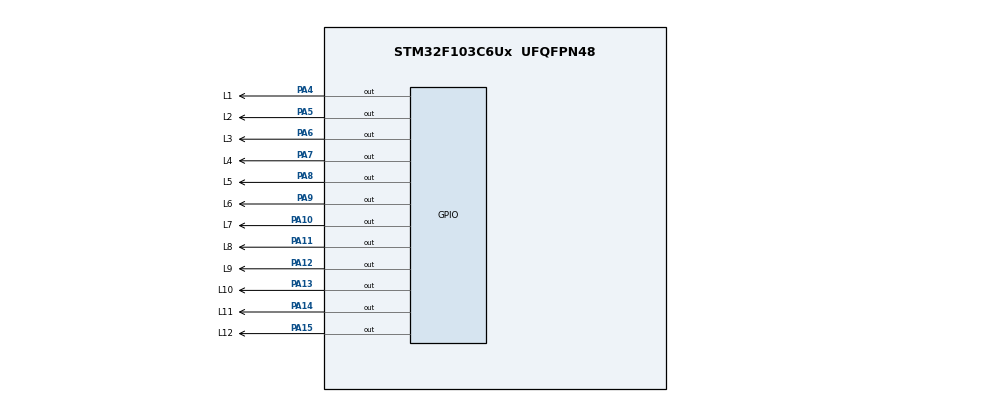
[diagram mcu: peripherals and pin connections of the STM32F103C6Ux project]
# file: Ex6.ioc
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Mcu.Family=STM32F1
Mcu.Name=STM32F103C6Ux
Mcu.Package=UFQFPN48
NVIC.PriorityGroup=NVIC_PRIORITYGROUP_4
PA10.GPIO_Label=L7
PA10.Signal=GPIO_Output
PA11.GPIO_Label=L8
PA11.Signal=GPIO_Output
PA12.GPIO_Label=L9
PA12.Signal=GPIO_Output
PA13.GPIO_Label=L10
PA13.Signal=GPIO_Output
PA14.GPIO_Label=L11
PA14.Signal=GPIO_Output
PA15.GPIO_Label=L12
PA15.Signal=GPIO_Output
PA4.GPIO_Label=L1
PA4.Signal=GPIO_Output
PA5.GPIO_Label=L2
PA5.Signal=GPIO_Output
PA6.GPIO_Label=L3
PA6.Signal=GPIO_Output
PA7.GPIO_Label=L4
PA7.Signal=GPIO_Output
PA8.GPIO_Label=L5
PA8.Signal=GPIO_Output
PA9.GPIO_Label=L6
PA9.Signal=GPIO_Output
ProjectManager.HeapSize=0x200
ProjectManager.StackSize=0x400
ProjectManager.TargetToolchain=STM32CubeIDE
RCC.APB1Freq_Value=8000000
RCC.APB2Freq_Value=8000000
board=custom

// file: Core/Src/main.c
/* USER CODE BEGIN Header */
/**
  ******************************************************************************
  * @file           : main.c
  * @brief          : Main program body
  ******************************************************************************
  * @attention
  *
  * Copyright (c) 2024 STMicroelectronics.
  * All rights reserved.
  *
  * This software is licensed under terms that can be found in the LICENSE file
  * in the root directory of this software component.
  * If no LICENSE file comes with this software, it is provided AS-IS.
  *
  ******************************************************************************
  */
/* USER CODE END Header */
#include "main.h"

void SystemClock_Config(void);
static void MX_GPIO_Init(void);

int main(void)
{

  /* MCU Configuration--------------------------------------------------------*/

  /* Reset of all peripherals, Initializes the Flash interface and the Systick. */
  HAL_Init();

  /* Configure the system clock */
  SystemClock_Config();

  /* Initialize all configured peripherals */
  MX_GPIO_Init();

  /* Infinite loop */
  /* USER CODE BEGIN WHILE */
  HAL_GPIO_WritePin(L1_GPIO_Port, L1_Pin, GPIO_PIN_SET);
  HAL_GPIO_WritePin(L2_GPIO_Port, L2_Pin, GPIO_PIN_SET);
  HAL_GPIO_WritePin(L3_GPIO_Port, L3_Pin, GPIO_PIN_SET);
  HAL_GPIO_WritePin(L4_GPIO_Port, L4_Pin, GPIO_PIN_SET);
  HAL_GPIO_WritePin(L5_GPIO_Port, L5_Pin, GPIO_PIN_SET);
  HAL_GPIO_WritePin(L6_GPIO_Port, L6_Pin, GPIO_PIN_SET);
  HAL_GPIO_WritePin(L7_GPIO_Port, L7_Pin, GPIO_PIN_SET);
  HAL_GPIO_WritePin(L8_GPIO_Port, L8_Pin, GPIO_PIN_SET);
  HAL_GPIO_WritePin(L9_GPIO_Port, L9_Pin, GPIO_PIN_SET);
  HAL_GPIO_WritePin(L10_GPIO_Port, L10_Pin, GPIO_PIN_SET);
  HAL_GPIO_WritePin(L11_GPIO_Port, L11_Pin, GPIO_PIN_SET);
  HAL_GPIO_WritePin(L12_GPIO_Port, L12_Pin, GPIO_PIN_SET);
  while (1)
  {
    /* USER CODE END WHILE */
	  HAL_GPIO_TogglePin(L1_GPIO_Port, L1_Pin);
	  HAL_Delay(1000);
	  HAL_GPIO_TogglePin(L2_GPIO_Port, L2_Pin);
	  HAL_Delay(1000);
	  HAL_GPIO_TogglePin(L3_GPIO_Port, L3_Pin);
	  HAL_Delay(1000);
	  HAL_GPIO_TogglePin(L4_GPIO_Port, L4_Pin);
	  HAL_Delay(1000);
	  HAL_GPIO_TogglePin(L5_GPIO_Port, L5_Pin);
	  HAL_Delay(1000);
	  HAL_GPIO_TogglePin(L6_GPIO_Port, L6_Pin);
	  HAL_Delay(1000);
	  HAL_GPIO_TogglePin(L7_GPIO_Port, L7_Pin);
	  HAL_Delay(1000);
	  HAL_GPIO_TogglePin(L8_GPIO_Port, L8_Pin);
	  HAL_Delay(1000);
	  HAL_GPIO_TogglePin(L9_GPIO_Port, L9_Pin);
	  HAL_Delay(1000);
	  HAL_GPIO_TogglePin(L10_GPIO_Port, L10_Pin);
	  HAL_Delay(1000);
	  HAL_GPIO_TogglePin(L11_GPIO_Port, L11_Pin);
	  HAL_Delay(1000);
	  HAL_GPIO_TogglePin(L12_GPIO_Port, L12_Pin);
	  HAL_Delay(1000);
  }
}

void SystemClock_Config(void)
{
  RCC_OscInitTypeDef RCC_OscInitStruct = {0};
  RCC_ClkInitTypeDef RCC_ClkInitStruct = {0};

  /** Initializes the RCC Oscillators according to the specified parameters
  * in the RCC_OscInitTypeDef structure.
  */
  RCC_OscInitStruct.OscillatorType = RCC_OSCILLATORTYPE_HSI;
  RCC_OscInitStruct.HSIState = RCC_HSI_ON;
  RCC_OscInitStruct.HSICalibrationValue = RCC_HSICALIBRATION_DEFAULT;
  RCC_OscInitStruct.PLL.PLLState = RCC_PLL_NONE;
  if (HAL_RCC_OscConfig(&RCC_OscInitStruct) != HAL_OK)
  {
    Error_Handler();
  }

  /** Initializes the CPU, AHB and APB buses clocks
  */
  RCC_ClkInitStruct.ClockType = RCC_CLOCKTYPE_HCLK|RCC_CLOCKTYPE_SYSCLK
                              |RCC_CLOCKTYPE_PCLK1|RCC_CLOCKTYPE_PCLK2;
  RCC_ClkInitStruct.SYSCLKSource = RCC_SYSCLKSOURCE_HSI;
  RCC_ClkInitStruct.AHBCLKDivider = RCC_SYSCLK_DIV1;
  RCC_ClkInitStruct.APB1CLKDivider = RCC_HCLK_DIV1;
  RCC_ClkInitStruct.APB2CLKDivider = RCC_HCLK_DIV1;

  if (HAL_RCC_ClockConfig(&RCC_ClkInitStruct, FLASH_LATENCY_0) != HAL_OK)
  {
    Error_Handler();
  }
}

static void MX_GPIO_Init(void)
{
  GPIO_InitTypeDef GPIO_InitStruct = {0};

  /* GPIO Ports Clock Enable */
  __HAL_RCC_GPIOA_CLK_ENABLE();

  /*Configure GPIO pin Output Level */
  HAL_GPIO_WritePin(GPIOA, L1_Pin|L2_Pin|L3_Pin|L4_Pin
                          |L5_Pin|L6_Pin|L7_Pin|L8_Pin
                          |L9_Pin|L10_Pin|L11_Pin|L12_Pin, GPIO_PIN_RESET);

  /*Configure GPIO pins : L1_Pin L2_Pin L3_Pin L4_Pin
                           L5_Pin L6_Pin L7_Pin L8_Pin
                           L9_Pin L10_Pin L11_Pin L12_Pin */
  GPIO_InitStruct.Pin = L1_Pin|L2_Pin|L3_Pin|L4_Pin
                          |L5_Pin|L6_Pin|L7_Pin|L8_Pin
                          |L9_Pin|L10_Pin|L11_Pin|L12_Pin;
  GPIO_InitStruct.Mode = GPIO_MODE_OUTPUT_PP;
  GPIO_InitStruct.Pull = GPIO_NOPULL;
  GPIO_InitStruct.Speed = GPIO_SPEED_FREQ_LOW;
  HAL_GPIO_Init(GPIOA, &GPIO_InitStruct);

}

void Error_Handler(void)
{
  __disable_irq();
  while (1)
  {
  }
}
